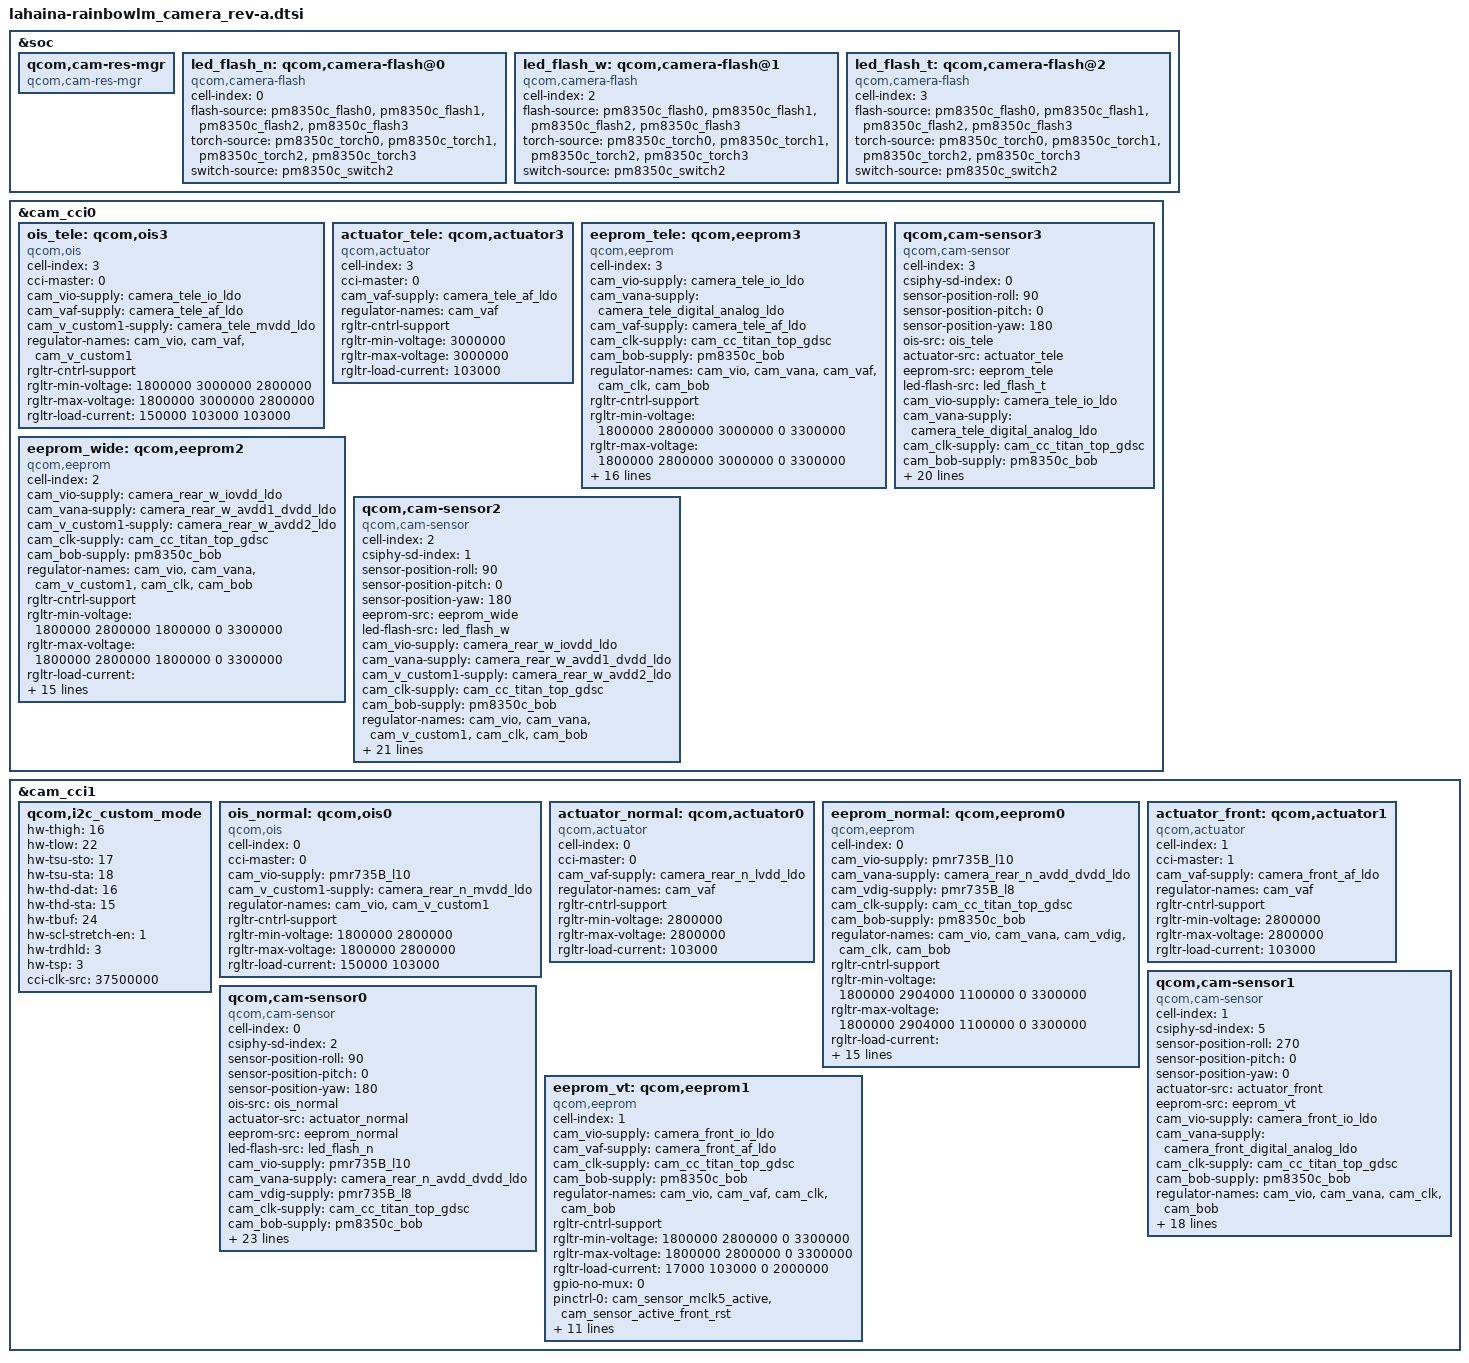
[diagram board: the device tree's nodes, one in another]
#include <dt-bindings/clock/qcom,camcc-lahaina.h>
#include "lahaina-rainbowlm_camera-flash.dtsi"
#include "lahaina-rainbowlm_camera-regulator.dtsi"

&soc {
	qcom,cam-res-mgr {
		compatible = "qcom,cam-res-mgr";
		status = "ok";
	};

	led_flash_n: qcom,camera-flash@0 {
		cell-index = <0>;
		compatible = "qcom,camera-flash";
		flash-source = <&pm8350c_flash0 &pm8350c_flash1
				&pm8350c_flash2 &pm8350c_flash3>;
		torch-source = <&pm8350c_torch0 &pm8350c_torch1
				&pm8350c_torch2 &pm8350c_torch3>;
		switch-source = <&pm8350c_switch2>;
		status = "ok";
	};

	led_flash_w: qcom,camera-flash@1 {
		cell-index = <2>;
		compatible = "qcom,camera-flash";
		flash-source = <&pm8350c_flash0 &pm8350c_flash1
				&pm8350c_flash2 &pm8350c_flash3>;
		torch-source = <&pm8350c_torch0 &pm8350c_torch1
				&pm8350c_torch2 &pm8350c_torch3>;
		switch-source = <&pm8350c_switch2>;
		status = "ok";
	};
	
	led_flash_t: qcom,camera-flash@2 {
		cell-index = <3>;
		compatible = "qcom,camera-flash";
		flash-source = <&pm8350c_flash0 &pm8350c_flash1
				&pm8350c_flash2 &pm8350c_flash3>;
		torch-source = <&pm8350c_torch0 &pm8350c_torch1
				&pm8350c_torch2 &pm8350c_torch3>;
		switch-source = <&pm8350c_switch2>;
		status = "ok";
	};
};

&cam_cci0 {
	ois_tele: qcom,ois3 {
		cell-index = <3>;
		compatible = "qcom,ois";
		cci-master = <0>;
		cam_vio-supply = <&camera_tele_io_ldo>;
		cam_vaf-supply = <&camera_tele_af_ldo>;
		cam_v_custom1-supply = <&camera_tele_mvdd_ldo>;
		regulator-names = "cam_vio", "cam_vaf", "cam_v_custom1";
		rgltr-cntrl-support;
		rgltr-min-voltage = <1800000 3000000 2800000>;
		rgltr-max-voltage = <1800000 3000000 2800000>;
		rgltr-load-current = <150000 103000 103000>;
		status = "ok";
	};

	actuator_tele: qcom,actuator3 {
		cell-index = <3>;
		compatible = "qcom,actuator";
		cci-master = <0>;
		cam_vaf-supply = <&camera_tele_af_ldo>;
		regulator-names = "cam_vaf";
		rgltr-cntrl-support;
		rgltr-min-voltage = <3000000>;
		rgltr-max-voltage = <3000000>;
		rgltr-load-current = <103000>;
	};

	eeprom_tele: qcom,eeprom3 {
		cell-index = <3>;
		compatible = "qcom,eeprom";
		cam_vio-supply = <&camera_tele_io_ldo>;
		cam_vana-supply = <&camera_tele_digital_analog_ldo>;
		cam_vaf-supply = <&camera_tele_af_ldo>;
		cam_clk-supply = <&cam_cc_titan_top_gdsc>;
		cam_bob-supply = <&pm8350c_bob>;
		regulator-names = "cam_vio", "cam_vana", "cam_vaf",
			"cam_clk", "cam_bob";
		rgltr-cntrl-support;
		rgltr-min-voltage = <1800000 2800000 3000000 0 3300000>;
		rgltr-max-voltage = <1800000 2800000 3000000 0 3300000>;
		rgltr-load-current = <17000 192000 103000 0 2000000>;
		gpio-no-mux = <0>;
		pinctrl-names = "cam_default", "cam_suspend";
		pinctrl-0 = <&cam_sensor_mclk0_active
				&cam_sensor_active_rst0>;
		pinctrl-1 = <&cam_sensor_mclk0_suspend
				&cam_sensor_suspend_rst0>;
		gpios = <&tlmm 100 0>,
			<&tlmm 17 0>;
		gpio-reset = <1>;
		gpio-req-tbl-num = <0 1>;
		gpio-req-tbl-flags = <1 0>;
		gpio-req-tbl-label = "CAMIF_MCLK0",
					"CAM_RESET0";
		cci-master = <0>;
		status = "ok";
		clocks = <&clock_camcc CAM_CC_MCLK0_CLK>;
		clock-names = "cam_clk";
		clock-cntl-level = "nominal";
		clock-rates = <19200000>;
	};

	qcom,cam-sensor3 {
		cell-index = <3>;
		compatible = "qcom,cam-sensor";
		csiphy-sd-index = <0>;
		sensor-position-roll = <90>;
		sensor-position-pitch = <0>;
		sensor-position-yaw = <180>;
		ois-src = <&ois_tele>;
		actuator-src = <&actuator_tele>;
		eeprom-src = <&eeprom_tele>;
		led-flash-src = <&led_flash_t>;
		cam_vio-supply = <&camera_tele_io_ldo>;
		cam_vana-supply = <&camera_tele_digital_analog_ldo>;
		cam_clk-supply = <&cam_cc_titan_top_gdsc>;
		cam_bob-supply = <&pm8350c_bob>;
		regulator-names = "cam_vio", "cam_vana",
			"cam_clk", "cam_bob";
		rgltr-cntrl-support;
		rgltr-min-voltage = <1800000 2800000 0 3300000>;
		rgltr-max-voltage = <1800000 2800000 0 3300000>;
		rgltr-load-current = <17000 192000 0 2000000>;
		gpio-no-mux = <0>;
		pinctrl-names = "cam_default", "cam_suspend";
		pinctrl-0 = <&cam_sensor_mclk0_active
				&cam_sensor_active_rst0>;
		pinctrl-1 = <&cam_sensor_mclk0_suspend
				&cam_sensor_suspend_rst0>;
		gpios = <&tlmm 100 0>,
			<&tlmm 17 0>;
		gpio-reset = <1>;
		gpio-req-tbl-num = <0 1>;
		gpio-req-tbl-flags = <1 0>;
		gpio-req-tbl-label = "CAMIF_MCLK0",
					"CAM_RESET0";
		cci-master = <0>;
		status = "ok";
		clocks = <&clock_camcc CAM_CC_MCLK0_CLK>;
		clock-names = "cam_clk";
		clock-cntl-level = "nominal";
		clock-rates = <19200000>;
	};

	eeprom_wide: qcom,eeprom2 {
		cell-index = <2>;
		compatible = "qcom,eeprom";
		cam_vio-supply = <&camera_rear_w_iovdd_ldo>;
		cam_vana-supply = <&camera_rear_w_avdd1_dvdd_ldo>;
		cam_v_custom1-supply = <&camera_rear_w_avdd2_ldo>;
		cam_clk-supply = <&cam_cc_titan_top_gdsc>;
		cam_bob-supply = <&pm8350c_bob>;
		regulator-names = "cam_vio", "cam_vana", "cam_v_custom1", "cam_clk", "cam_bob";
		rgltr-cntrl-support;
		rgltr-min-voltage = <1800000 2800000 1800000 0 3300000>;
		rgltr-max-voltage = <1800000 2800000 1800000 0 3300000>;
		rgltr-load-current = <10000 52000 10000 0 2000000>;
		gpio-no-mux = <0>;
		pinctrl-names = "cam_default", "cam_suspend";
		pinctrl-0 = <&cam_sensor_mclk1_active
				&cam_sensor_active_rst1>;
		pinctrl-1 = <&cam_sensor_mclk1_suspend
				&cam_sensor_suspend_rst1>;
		gpios = <&tlmm 101 0>,
			<&tlmm 16 0>;
		gpio-reset = <1>;
		gpio-req-tbl-num = <0 1>;
		gpio-req-tbl-flags = <1 0>;
		gpio-req-tbl-label = "CAMIF_MCLK1",
					"CAM_RESET1";
		cci-master = <1>;
		status = "ok";
		clocks = <&clock_camcc CAM_CC_MCLK1_CLK>;
		clock-names = "cam_clk";
		clock-cntl-level = "nominal";
		clock-rates = <19200000>;
	};

	qcom,cam-sensor2 {
		cell-index = <2>;
		compatible = "qcom,cam-sensor";
		csiphy-sd-index = <1>;
		sensor-position-roll = <90>;
		sensor-position-pitch = <0>;
		sensor-position-yaw = <180>;
		eeprom-src = <&eeprom_wide>;
		led-flash-src = <&led_flash_w>;
		cam_vio-supply = <&camera_rear_w_iovdd_ldo>;
		cam_vana-supply = <&camera_rear_w_avdd1_dvdd_ldo>;
		cam_v_custom1-supply = <&camera_rear_w_avdd2_ldo>;
		cam_clk-supply = <&cam_cc_titan_top_gdsc>;
		cam_bob-supply = <&pm8350c_bob>;
		regulator-names = "cam_vio", "cam_vana", "cam_v_custom1", "cam_clk", "cam_bob";
		rgltr-cntrl-support;
		rgltr-min-voltage = <1800000 2800000 1800000 0 3300000>;
		rgltr-max-voltage = <1800000 2800000 1800000 0 3300000>;
		rgltr-load-current = <10000 52000 10000 0 2000000>;
		gpio-no-mux = <0>;
		pinctrl-names = "cam_default", "cam_suspend";
		pinctrl-0 = <&cam_sensor_mclk1_active
				&cam_sensor_active_rst1>;
		pinctrl-1 = <&cam_sensor_mclk1_suspend
				&cam_sensor_suspend_rst1>;
		gpios = <&tlmm 101 0>,
			<&tlmm 16 0>;
		gpio-reset = <1>;
		gpio-req-tbl-num = <0 1>;
		gpio-req-tbl-flags = <1 0>;
		gpio-req-tbl-label = "CAMIF_MCLK1",
					"CAM_RESET1";
		cci-master = <1>;
		status = "ok";
		clocks = <&clock_camcc CAM_CC_MCLK1_CLK>;
		clock-names = "cam_clk";
		clock-cntl-level = "nominal";
		clock-rates = <19200000>;
	};
};

&cam_cci1 {
	qcom,i2c_custom_mode {
		hw-thigh = <16>;
		hw-tlow = <22>;
		hw-tsu-sto = <17>;
		hw-tsu-sta = <18>;
		hw-thd-dat = <16>;
		hw-thd-sta = <15>;
		hw-tbuf = <24>;
		hw-scl-stretch-en = <1>;
		hw-trdhld = <3>;
		hw-tsp = <3>;
		cci-clk-src = <37500000>;
		status = "ok";
	};

	ois_normal: qcom,ois0 {
		cell-index = <0>;
		compatible = "qcom,ois";
		cci-master = <0>;
		cam_vio-supply = <&pmr735B_l10>;
		cam_v_custom1-supply = <&camera_rear_n_mvdd_ldo>;
		regulator-names = "cam_vio", "cam_v_custom1";
		rgltr-cntrl-support;
		rgltr-min-voltage = <1800000 2800000>;
		rgltr-max-voltage = <1800000 2800000>;
		rgltr-load-current = <150000 103000>;
		status = "ok";
	};

	actuator_normal: qcom,actuator0 {
		cell-index = <0>;
		compatible = "qcom,actuator";
		cci-master = <0>;
		cam_vaf-supply = <&camera_rear_n_lvdd_ldo>;
		regulator-names = "cam_vaf";
		rgltr-cntrl-support;
		rgltr-min-voltage = <2800000>;
		rgltr-max-voltage = <2800000>;
		rgltr-load-current = <103000>;
	};

	eeprom_normal: qcom,eeprom0 {
		cell-index = <0>;
		compatible = "qcom,eeprom";
		cam_vio-supply = <&pmr735B_l10>;
		cam_vana-supply = <&camera_rear_n_avdd_dvdd_ldo>;
		cam_vdig-supply = <&pmr735B_l8>;
		cam_clk-supply = <&cam_cc_titan_top_gdsc>;
		cam_bob-supply = <&pm8350c_bob>;
		regulator-names = "cam_vio", "cam_vana", "cam_vdig", "cam_clk", "cam_bob";
		rgltr-cntrl-support;
		rgltr-min-voltage = <1800000 2904000 1100000 0 3300000>;
		rgltr-max-voltage = <1800000 2904000 1100000 0 3300000>;
		rgltr-load-current = <150000 150000 805000 0 150000>;
		gpio-no-mux = <0>;
		pinctrl-names = "cam_default", "cam_suspend";
		pinctrl-0 = <&cam_sensor_mclk2_active
				&cam_sensor_active_rst2>;
		pinctrl-1 = <&cam_sensor_mclk2_suspend
				&cam_sensor_suspend_rst2>;
		gpios = <&tlmm 102 0>,
			<&tlmm 106 0>;
		gpio-reset = <1>;
		gpio-req-tbl-num = <0 1>;
		gpio-req-tbl-flags = <1 0>;
		gpio-req-tbl-label = "CAMIF_MCLK2",
					"CAM_RESET2";
		cci-master = <0>;
		status = "ok";
		clocks = <&clock_camcc CAM_CC_MCLK2_CLK>;
		clock-names = "cam_clk";
		clock-cntl-level = "nominal";
		clock-rates = <19200000>;
	};

	qcom,cam-sensor0 {
		cell-index = <0>;
		compatible = "qcom,cam-sensor";
		csiphy-sd-index = <2>;
		sensor-position-roll = <90>;
		sensor-position-pitch = <0>;
		sensor-position-yaw = <180>;
		ois-src = <&ois_normal>;
		actuator-src = <&actuator_normal>;
		eeprom-src = <&eeprom_normal>;
		led-flash-src = <&led_flash_n>;
		cam_vio-supply = <&pmr735B_l10>;
		cam_vana-supply = <&camera_rear_n_avdd_dvdd_ldo>;
		cam_vdig-supply = <&pmr735B_l8>;
		cam_clk-supply = <&cam_cc_titan_top_gdsc>;
		cam_bob-supply = <&pm8350c_bob>;
		regulator-names = "cam_vio", "cam_vana", "cam_vdig", "cam_clk", "cam_bob";
		rgltr-cntrl-support;
		rgltr-min-voltage = <1800000 2904000 1100000 0 3300000>;
		rgltr-max-voltage = <1800000 2904000 1100000 0 3300000>;
		rgltr-load-current = <150000 150000 805000 0 150000>;
		gpio-no-mux = <0>;
		pinctrl-names = "cam_default", "cam_suspend";
		pinctrl-0 = <&cam_sensor_mclk2_active
				&cam_sensor_active_rst2>;
		pinctrl-1 = <&cam_sensor_mclk2_suspend
				&cam_sensor_suspend_rst2>;
		gpios = <&tlmm 102 0>,
			<&tlmm 106 0>;
		gpio-reset = <1>;
		gpio-req-tbl-num = <0 1>;
		gpio-req-tbl-flags = <1 0>;
		gpio-req-tbl-label = "CAMIF_MCLK2",
					"CAM_RESET2";
		cci-master = <0>;
		status = "ok";
		clocks = <&clock_camcc CAM_CC_MCLK2_CLK>;
		clock-names = "cam_clk";
		clock-cntl-level = "nominal";
		clock-rates = <19200000>;
	};

	actuator_front: qcom,actuator1 {
		cell-index = <1>;
		compatible = "qcom,actuator";
		cci-master = <1>;
		cam_vaf-supply = <&camera_front_af_ldo>;
		regulator-names = "cam_vaf";
		rgltr-cntrl-support;
		rgltr-min-voltage = <2800000>;
		rgltr-max-voltage = <2800000>;
		rgltr-load-current = <103000>;
	};

	eeprom_vt: qcom,eeprom1 {
		cell-index = <1>;
		compatible = "qcom,eeprom";
		cam_vio-supply = <&camera_front_io_ldo>;
		cam_vaf-supply = <&camera_front_af_ldo>;
		cam_clk-supply = <&cam_cc_titan_top_gdsc>;
		cam_bob-supply = <&pm8350c_bob>;
		regulator-names = "cam_vio", "cam_vaf",
			"cam_clk", "cam_bob";
		rgltr-cntrl-support;
		rgltr-min-voltage = <1800000 2800000 0 3300000>;
		rgltr-max-voltage = <1800000 2800000 0 3300000>;
		rgltr-load-current = <17000 103000 0 2000000>;
		gpio-no-mux = <0>;
		pinctrl-names = "cam_default", "cam_suspend";
		pinctrl-0 = <&cam_sensor_mclk5_active
				 &cam_sensor_active_front_rst>;
		pinctrl-1 = <&cam_sensor_mclk5_suspend
				 &cam_sensor_suspend_front_rst>;
		gpios = <&tlmm 105 0>,
			<&tlmm 115 0>;
		gpio-reset = <1>;
		gpio-req-tbl-num = <0 1>;
		gpio-req-tbl-flags = <1 0>;
		gpio-req-tbl-label = "CAMIF_MCLK5",
					"CAM_RESET5";
		cci-master = <1>;
		status = "ok";
		clocks = <&clock_camcc CAM_CC_MCLK5_CLK>;
		clock-names = "cam_clk";
		clock-cntl-level = "nominal";
		clock-rates = <19200000>;
	};

	qcom,cam-sensor1 {
		cell-index = <1>;
		compatible = "qcom,cam-sensor";
		csiphy-sd-index = <5>;
		sensor-position-roll = <270>;
		sensor-position-pitch = <0>;
		sensor-position-yaw = <0>;
		actuator-src = <&actuator_front>;
		eeprom-src = <&eeprom_vt>;
		cam_vio-supply = <&camera_front_io_ldo>;
		cam_vana-supply = <&camera_front_digital_analog_ldo>;
		cam_clk-supply = <&cam_cc_titan_top_gdsc>;
		cam_bob-supply = <&pm8350c_bob>;
		regulator-names = "cam_vio", "cam_vana",
			"cam_clk", "cam_bob";
		rgltr-cntrl-support;
		rgltr-min-voltage = <1800000 3000000 0 3300000>;
		rgltr-max-voltage = <1800000 3000000 0 3300000>;
		rgltr-load-current = <17000 192000 0 2000000>;
		gpio-no-mux = <0>;
		pinctrl-names = "cam_default", "cam_suspend";
		pinctrl-0 = <&cam_sensor_mclk5_active
				 &cam_sensor_active_front_rst>;
		pinctrl-1 = <&cam_sensor_mclk5_suspend
				 &cam_sensor_suspend_front_rst>;
		gpios = <&tlmm 105 0>,
			<&tlmm 115 0>;
		gpio-reset = <1>;
		gpio-req-tbl-num = <0 1>;
		gpio-req-tbl-flags = <1 0>;
		gpio-req-tbl-label = "CAMIF_MCLK5",
					"CAM_RESET5";
		cci-master = <1>;
		status = "ok";
		clocks = <&clock_camcc CAM_CC_MCLK5_CLK>;
		clock-names = "cam_clk";
		clock-cntl-level = "nominal";
		clock-rates = <19200000>;
	};
};
